AUTOSAR XML (schema 314)
package /ComponentType
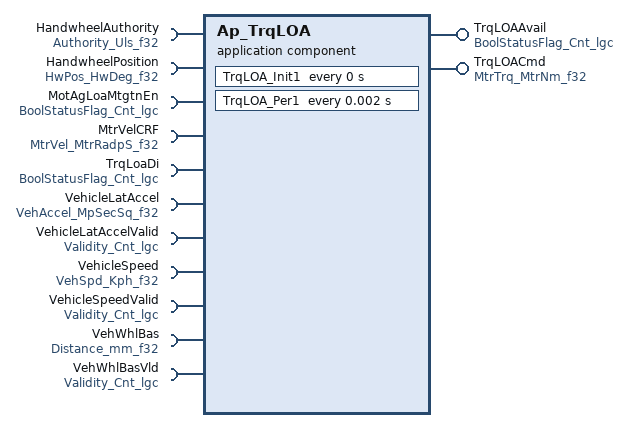
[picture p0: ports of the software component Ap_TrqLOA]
  application software component type Ap_TrqLOA
    provide port TrqLOAAvail: unqueued-sender-com-spec{data-element=Cnt_lgc, can-invalidate=false, init-value=D_FALSE_CNT_LGC}, provided-interface=BoolStatusFlag_Cnt_lgc
    provide port TrqLOACmd: unqueued-sender-com-spec{data-element=MtrNm_f32, can-invalidate=false, init-value=D_ZERO_ULS_F32}, provided-interface=MtrTrq_MtrNm_f32
    11 x require port:
      HandwheelAuthority: unqueued-receiver-com-spec{data-element=Uls_f32, init-value=D_ZERO_ULS_F32}, required-interface=Authority_Uls_f32
      HandwheelPosition: unqueued-receiver-com-spec{data-element=HwDeg_f32, init-value=D_ZERO_ULS_F32}, required-interface=HwPos_HwDeg_f32
      MotAgLoaMtgtnEn: unqueued-receiver-com-spec{data-element=Cnt_lgc, init-value=D_FALSE_CNT_LGC}, required-interface=BoolStatusFlag_Cnt_lgc
      MtrVelCRF: unqueued-receiver-com-spec{data-element=MtrRadpS_f32, init-value=D_ZERO_ULS_F32}, required-interface=MtrVel_MtrRadpS_f32
      TrqLoaDi: unqueued-receiver-com-spec{data-element=Cnt_lgc, init-value=D_FALSE_CNT_LGC}, required-interface=BoolStatusFlag_Cnt_lgc
      VehicleLatAccel: unqueued-receiver-com-spec{data-element=MpSecSq_f32, init-value=D_ZERO_ULS_F32}, required-interface=VehAccel_MpSecSq_f32
      VehicleLatAccelValid: unqueued-receiver-com-spec{data-element=Cnt_lgc, init-value=D_FALSE_CNT_LGC}, required-interface=Validity_Cnt_lgc
      VehicleSpeed: unqueued-receiver-com-spec{data-element=Kph_f32, init-value=D_ZERO_ULS_F32}, required-interface=VehSpd_Kph_f32
      VehicleSpeedValid: unqueued-receiver-com-spec{data-element=Cnt_lgc, init-value=D_FALSE_CNT_LGC}, required-interface=Validity_Cnt_lgc
      VehWhlBas: unqueued-receiver-com-spec{data-element=mm_f32, init-value=D_VEHWHLBASEINIT_MM_F32}, required-interface=Distance_mm_f32
      VehWhlBasVld: unqueued-receiver-com-spec{data-element=Cnt_lgc, init-value=D_FALSE_CNT_LGC}, required-interface=Validity_Cnt_lgc
  internal behavior Ap_TrqLOA_InternalBehavior: component=Ap_TrqLOA
    timing event TrqLOA_Init1_InitEvent: start-on-event=TrqLOA_Init1, period=0
    timing event TMT_TrqLOA_Per1: start-on-event=TrqLOA_Per1, period=0.002
    port-api-options:
      enable-take-address=false, indirect-api=false, port=HandwheelAuthority
      enable-take-address=false, indirect-api=false, port=HandwheelPosition
      enable-take-address=false, indirect-api=false, port=MotAgLoaMtgtnEn
      enable-take-address=false, indirect-api=false, port=MtrVelCRF
      enable-take-address=false, indirect-api=false, port=TrqLOAAvail
      enable-take-address=false, indirect-api=false, port=TrqLOACmd
      enable-take-address=false, indirect-api=false, port=TrqLoaDi
      enable-take-address=false, indirect-api=false, port=VehicleLatAccel
      enable-take-address=false, indirect-api=false, port=VehicleLatAccelValid
      enable-take-address=false, indirect-api=false, port=VehicleSpeed
      enable-take-address=false, indirect-api=false, port=VehicleSpeedValid
      enable-take-address=false, indirect-api=false, port=VehWhlBas
      enable-take-address=false, indirect-api=false, port=VehWhlBasVld
    runnable TrqLOA_Init1
    runnable TrqLOA_Per1
      11 x data read access:
        READ_HandwheelAuthority_Uls_f32: data-element=HandwheelAuthority.Uls_f32
        READ_HandwheelPosition_HwDeg_f32: data-element=HandwheelPosition.HwDeg_f32
        READ_MotAgLoaMtgtnEn_Cnt_lgc: data-element=MotAgLoaMtgtnEn.Cnt_lgc
        READ_MtrVelCRF_MtrRadpS_f32: data-element=MtrVelCRF.MtrRadpS_f32
        READ_TrqLoaDi_Cnt_lgc: data-element=TrqLoaDi.Cnt_lgc
        READ_VehicleLatAccel_MpSecSq_f32: data-element=VehicleLatAccel.MpSecSq_f32
        READ_VehicleLatAccelValid_Cnt_lgc: data-element=VehicleLatAccelValid.Cnt_lgc
        READ_VehicleSpeed_Kph_f32: data-element=VehicleSpeed.Kph_f32
        READ_VehicleSpeedValid_Cnt_lgc: data-element=VehicleSpeedValid.Cnt_lgc
        READ_VehWhlBas_mm_f32: data-element=VehWhlBas.mm_f32
        READ_VehWhlBasVld_Cnt_lgc: data-element=VehWhlBasVld.Cnt_lgc
      data write access WRITE_TrqLOAAvail_Cnt_lgc: data-element=TrqLOAAvail.Cnt_lgc
      data write access WRITE_TrqLOACmd_MtrNm_f32: data-element=TrqLOACmd.MtrNm_f32
  swc implementation Ap_TrqLOA_Implementation: behavior=Ap_TrqLOA_InternalBehavior
    code-descriptors:
      code Code: type=SRC
